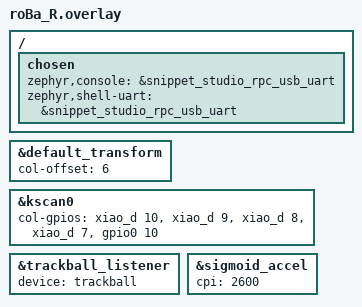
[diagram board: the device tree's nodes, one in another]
#include "roBa.dtsi"
#include "roBa_R_trackball.dtsi"

&default_transform {
    col-offset = <6>;
};

&kscan0 {
        col-gpios
            = <&xiao_d 10 GPIO_ACTIVE_HIGH>
            , <&xiao_d 9 GPIO_ACTIVE_HIGH> 
            , <&xiao_d 8 GPIO_ACTIVE_HIGH> 
            , <&xiao_d 7 GPIO_ACTIVE_HIGH> 
            , <&gpio0 10 GPIO_ACTIVE_HIGH>
            ;
};

/ {
    chosen {
        zephyr,console = &snippet_studio_rpc_usb_uart;
        zephyr,shell-uart = &snippet_studio_rpc_usb_uart;
    };
};

&trackball_listener {
    status = "okay";
    device = <&trackball>;
};

&sigmoid_accel {
    cpi = <2600>;
};
